# DSS_PRM register map
Vendor: Texas Instruments
Peripheral module from a debugger description file (folder omap4460).
Registers are 32-bit, access not given, reset 0x30000 unless marked. A register's access mark holds for its fields unless they carry their own. Offsets are as the file gives them; lines under a group give offsets from that group; [hi:lo] are bit positions; {n}, {i} and the like mark numbered series; 'fields as' and 'values as' point back to an identical list; <NAME> marks a mode.

## DSS_PRM
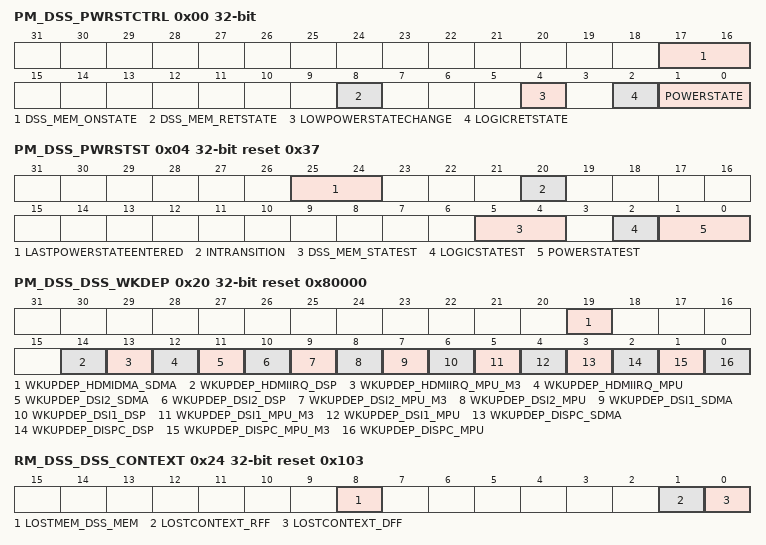
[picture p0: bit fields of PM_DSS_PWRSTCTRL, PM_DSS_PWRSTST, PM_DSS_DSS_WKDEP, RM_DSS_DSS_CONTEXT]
0x00 PM_DSS_PWRSTCTRL — This register controls the DSS power state to reach upon a domain sleep transition
  [17:16] DSS_MEM_ONSTATE — DSS_MEM state when domain is ON. (access R Rreturns1s)
    3=DSS_MEM_ONSTATE_3_r (Memory bank is on when the domain is ON.)
  [8] DSS_MEM_RETSTATE ro — DSS_MEM state when domain is RETENTION.
    0=DSS_MEM_RETSTATE_0_r (Memory bank is off when the domain is in the RETENTION state.)
  [4] LOWPOWERSTATECHANGE — Power state change request when domain has already performed a sleep transition. Allows going into deeper low power state without waking up the power domain. (access RW WSpecial)
    0=Do not request a low power state change; 1=Request a low power state change. This bit is automatically cleared when the power state is effectively changed or when power state is ON.
  [2] LOGICRETSTATE ro — Logic state when power domain is RETENTION
    0=LOGICRETSTATE_0_r (Whole logic is off when the domain is in RETENTION state.)
  [1:0] POWERSTATE rw — Power state control
    0=OFF state; 1=RETENTION state; 2=INACTIVE state; 3=ON State
0x04 PM_DSS_PWRSTST reset 0x37 — This register provides a status on the current DSS power domain state. [warm reset insensitive]
  [25:24] LASTPOWERSTATEENTERED — Last low power state entered. Set to 0x3 upon write of the same only. This register is intended for debug purpose only. (access RW W1toSet)
    3=LASTPOWERSTATEENTERED_3_r (Power domain was previously OFF); 2=LASTPOWERSTATEENTERED_2_r (Power domain was previously in RETENTION); 1=LASTPOWERSTATEENTERED_1_r (Power domain was previously ON-INACTIVE); 0=LASTPOWERSTATEENTERED_0_r (Power domain was previously ON-ACTIVE)
  [20] INTRANSITION ro — Domain transition status
    0=INTRANSITION_0_r (No ongoing transition on power domain); 1=INTRANSITION_1_r (Power domain transition is in progress.)
  [5:4] DSS_MEM_STATEST ro — DSS_MEM state status
    0=DSS_MEM_STATEST_0_r (Memory is OFF); 1=DSS_MEM_STATEST_1_r (Reserved); 2=DSS_MEM_STATEST_2_r (Reserved); 3=DSS_MEM_STATEST_3_r (Memory is ON)
  [2] LOGICSTATEST ro — Logic state status
    0=LOGICSTATEST_0_r (Logic in domain is OFF); 1=LOGICSTATEST_1_r (Logic in domain is ON)
  [1:0] POWERSTATEST ro — Current power state status
    0=POWERSTATEST_0_r (Power domain is OFF); 1=POWERSTATEST_1_r (Power domain is in RETENTION); 2=POWERSTATEST_2_r (Power domain is ON-INACTIVE); 3=POWERSTATEST_3_r (Power domain is ON-ACTIVE)
0x20 PM_DSS_DSS_WKDEP reset 0x80000 — This register controls wakeup dependency based on DSS service requests.
  [19] WKUPDEP_HDMIDMA_SDMA — Wakeup dependency from HDMI module (SWakeup_HDMI_dma signal) towards SDMA + L3_2 domains (access R Rreturns1s)
    1=WKUPDEP_HDMIDMA_SDMA_1_r (Dependency is enabled)
  [14] WKUPDEP_HDMIIRQ_DSP rw — Wakeup dependency from HDMI module (softwareakeup_HDMI_irq signal) towards DSP + L3_1 + L3_2 domains
    0=Dependency is disabled; 1=Dependency is enabled
  [13] WKUPDEP_HDMIIRQ_MPU_M3 rw — Wakeup dependency from HDMI module (softwareakeup_HDMI_irq signal) towards MPU_A3 + L3_2 domains
    0=Dependency is disabled; 1=Dependency is enabled
  [12] WKUPDEP_HDMIIRQ_MPU rw — Wakeup dependency from HDMI module (softwareakeup_HDMI_irq signal) towards MPU + L3_1 + L3_2 domains
    0=Dependency is disabled; 1=Dependency is enabled
  [11] WKUPDEP_DSI2_SDMA rw — Wakeup dependency from DSI2 module (softwareakeup_DSI2 signal) towards SDMA + L3_2 domains
    0=Dependency is disabled; 1=Dependency is enabled
  [10] WKUPDEP_DSI2_DSP rw — Wakeup dependency from DSI2 module (softwareakeup_DSI2 signal) towards DSP + L3_1 + L3_2 domains
    0=Dependency is disabled; 1=Dependency is enabled
  [9] WKUPDEP_DSI2_MPU_M3 rw — Wakeup dependency from DSI2 module (softwareakeup_DSI2 signal) towards MPU_A3 + L3_2 domains
    0=Dependency is disabled; 1=Dependency is enabled
  [8] WKUPDEP_DSI2_MPU rw — Wakeup dependency from DSI2 module (softwareakeup_DSI2 signal) towards MPU + L3_1 + L3_2 domains
    0=Dependency is disabled; 1=Dependency is enabled
  [7] WKUPDEP_DSI1_SDMA rw — Wakeup dependency from DSI1 module (softwareakeup_DSI1 signal) towards SDMA + L3_2 domains
    0=Dependency is disabled; 1=Dependency is enabled
  [6] WKUPDEP_DSI1_DSP rw — Wakeup dependency from DSI1 module (softwareakeup_DSI1 signal) towards DSP + L3_1 + L3_2 domains
    0=Dependency is disabled; 1=Dependency is enabled
  [5] WKUPDEP_DSI1_MPU_M3 rw — Wakeup dependency from DSI1 module (softwareakeup_DSI1 signal) towards MPU_A3 + L3_2 domains
    0=Dependency is disabled; 1=Dependency is enabled
  [4] WKUPDEP_DSI1_MPU rw — Wakeup dependency from DSI1 module (softwareakeup_DSI1 signal) towards MPU + L3_1 + L3_2 domains
    0=Dependency is disabled; 1=Dependency is enabled
  [3] WKUPDEP_DISPC_SDMA rw — Wakeup dependency from DISPC module (softwareakeup_DISPC signal) towards SDMA + L3_2 domains
    0=Dependency is disabled; 1=Dependency is enabled
  [2] WKUPDEP_DISPC_DSP rw — Wakeup dependency from DISPC module (softwareakeup_DISPC signal) towards DSP + L3_1 + L3_2 domains
    0=Dependency is disabled; 1=Dependency is enabled
  [1] WKUPDEP_DISPC_MPU_M3 rw — Wakeup dependency from DISPC module (softwareakeup_DISPC signal) towards MPU_A3 + L3_2 domains
    0=Dependency is disabled; 1=Dependency is enabled
  [0] WKUPDEP_DISPC_MPU rw — Wakeup dependency from DISPC module (softwareakeup_DISPC signal) towards MPU + L3_1 + L3_2 domains
    0=Dependency is disabled; 1=Dependency is enabled
0x24 RM_DSS_DSS_CONTEXT reset 0x103 — This register contains dedicated DSS context statuses. [warm reset insensitive]
  [all] fields
    0=Context has been maintained; 1=Context has been lost
  [8] LOSTMEM_DSS_MEM — Specify if memory-based context in DSS_MEM memory bank has been lost due to a previous power transition or other reset source. (access RW W1toClr)
  [1] LOSTCONTEXT_RFF — Specify if RFF-based context has been lost due to a previous power transition or other reset source. (set upon assertion of DSS_RET_RST signal) (access RW W1toClr)
  [0] LOSTCONTEXT_DFF — Specify if DFF-based context has been lost due to a previous power transition or other reset source. (set upon assertion of DSS_RST signal) (access RW W1toClr)
